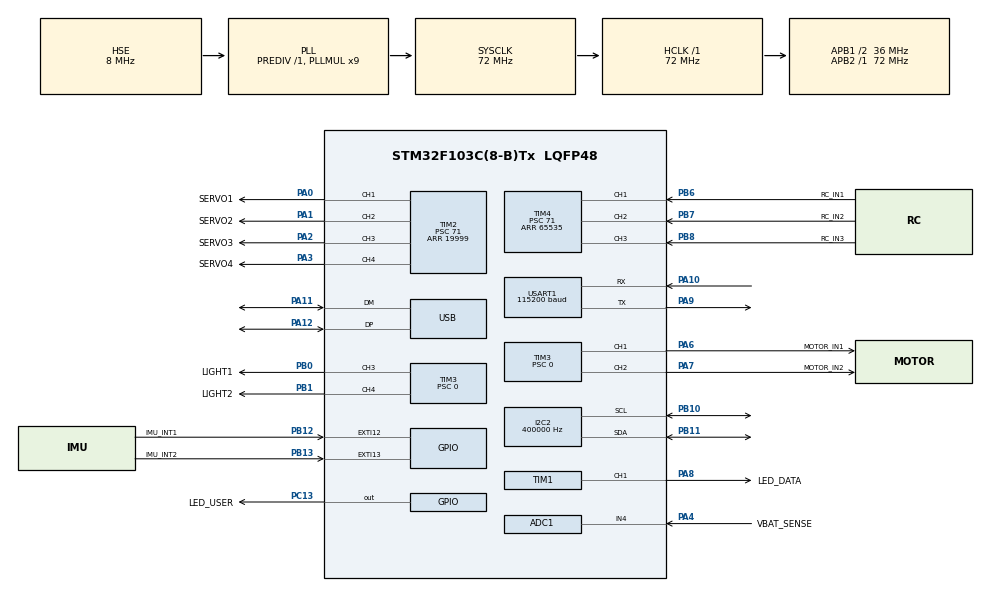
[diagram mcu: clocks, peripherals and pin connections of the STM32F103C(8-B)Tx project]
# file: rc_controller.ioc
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ADC1.Channel-0\#ChannelRegularConversion=ADC_CHANNEL_4
ADC1.NbrOfConversionFlag=1
ADC1.Rank-0\#ChannelRegularConversion=1
ADC1.SamplingTime-0\#ChannelRegularConversion=ADC_SAMPLETIME_1CYCLE_5
ADC1.master=1
Dma.Request0=TIM1_CH1
Dma.TIM1_CH1.0.Direction=DMA_MEMORY_TO_PERIPH
Dma.TIM1_CH1.0.Instance=DMA1_Channel2
Dma.TIM1_CH1.0.MemDataAlignment=DMA_MDATAALIGN_HALFWORD
Dma.TIM1_CH1.0.MemInc=DMA_MINC_ENABLE
Dma.TIM1_CH1.0.Mode=DMA_NORMAL
Dma.TIM1_CH1.0.PeriphDataAlignment=DMA_PDATAALIGN_HALFWORD
Dma.TIM1_CH1.0.PeriphInc=DMA_PINC_DISABLE
Dma.TIM1_CH1.0.Priority=DMA_PRIORITY_HIGH
I2C2.ClockSpeed=400000
Mcu.Family=STM32F1
Mcu.Name=STM32F103C(8-B)Tx
Mcu.Package=LQFP48
NVIC.DMA1_Channel2_IRQn=true\:0\:0\:false\:false\:true\:false\:true\:true
NVIC.EXTI15_10_IRQn=true\:0\:0\:false\:false\:true\:true\:true\:true
NVIC.PriorityGroup=NVIC_PRIORITYGROUP_4
NVIC.TIM4_IRQn=true\:0\:0\:false\:false\:true\:true\:true\:true
NVIC.USB_LP_CAN1_RX0_IRQn=true\:0\:0\:false\:false\:true\:false\:true\:true
PA0-WKUP.GPIO_Label=SERVO1
PA0-WKUP.Signal=S_TIM2_CH1_ETR
PA1.GPIO_Label=SERVO2
PA1.Signal=S_TIM2_CH2
PA10.Mode=Asynchronous
PA10.Signal=USART1_RX
PA11.Mode=Device
PA11.Signal=USB_DM
PA12.Mode=Device
PA12.Signal=USB_DP
PA13.Mode=Trace_Asynchronous_SW
PA13.Signal=SYS_JTMS-SWDIO
PA14.Mode=Trace_Asynchronous_SW
PA14.Signal=SYS_JTCK-SWCLK
PA2.GPIO_Label=SERVO3
PA2.Signal=S_TIM2_CH3
PA3.GPIO_Label=SERVO4
PA3.Signal=S_TIM2_CH4
PA4.GPIO_Label=VBAT_SENSE
PA4.Signal=ADCx_IN4
PA6.GPIO_Label=MOTOR_IN1
PA6.Signal=S_TIM3_CH1
PA7.GPIO_Label=MOTOR_IN2
PA7.Signal=S_TIM3_CH2
PA8.GPIO_Label=LED_DATA
PA8.Signal=S_TIM1_CH1
PA9.Mode=Asynchronous
PA9.Signal=USART1_TX
PB0.GPIO_Label=LIGHT1
PB0.Signal=S_TIM3_CH3
PB1.GPIO_Label=LIGHT2
PB1.Signal=S_TIM3_CH4
PB10.Mode=I2C
PB10.Signal=I2C2_SCL
PB11.Mode=I2C
PB11.Signal=I2C2_SDA
PB12.GPIO_Label=IMU_INT1
PB12.GPIO_ModeDefaultEXTI=GPIO_MODE_IT_RISING
PB12.Signal=GPXTI12
PB13.GPIO_Label=IMU_INT2
PB13.GPIO_ModeDefaultEXTI=GPIO_MODE_IT_RISING
PB13.Signal=GPXTI13
PB3.Mode=Trace_Asynchronous_SW
PB3.Signal=SYS_JTDO-TRACESWO
PB6.GPIO_Label=RC_IN1
PB6.Signal=S_TIM4_CH1
PB7.GPIO_Label=RC_IN2
PB7.Signal=S_TIM4_CH2
PB8.GPIO_Label=RC_IN3
PB8.Signal=S_TIM4_CH3
PC13-TAMPER-RTC.GPIO_Label=LED_USER
PC13-TAMPER-RTC.PinState=GPIO_PIN_SET
PC13-TAMPER-RTC.Signal=GPIO_Output
PD0-OSC_IN.Mode=HSE-External-Oscillator
PD0-OSC_IN.Signal=RCC_OSC_IN
PD1-OSC_OUT.Mode=HSE-External-Oscillator
PD1-OSC_OUT.Signal=RCC_OSC_OUT
ProjectManager.HeapSize=0x200
ProjectManager.StackSize=0x400
ProjectManager.TargetToolchain=CMake
RCC.ADCPresc=RCC_ADCPCLK2_DIV6
RCC.AHBFreq_Value=72000000
RCC.APB1CLKDivider=RCC_HCLK_DIV2
RCC.APB1Freq_Value=36000000
RCC.APB1TimFreq_Value=72000000
RCC.APB2Freq_Value=72000000
RCC.APB2TimFreq_Value=72000000
RCC.HCLKFreq_Value=72000000
RCC.PLLMUL=RCC_PLL_MUL9
RCC.PLLSourceVirtual=RCC_PLLSOURCE_HSE
RCC.SYSCLKFreq_VALUE=72000000
RCC.SYSCLKSource=RCC_SYSCLKSOURCE_PLLCLK
RCC.USBFreq_Value=48000000
RCC.USBPrescaler=RCC_USBCLKSOURCE_PLL_DIV1_5
SH.ADCx_IN4.0=ADC1_IN4,IN4
SH.S_TIM1_CH1.0=TIM1_CH1,PWM Generation1 CH1
SH.S_TIM2_CH1_ETR.0=TIM2_CH1,PWM Generation1 CH1
SH.S_TIM2_CH2.0=TIM2_CH2,PWM Generation2 CH2
SH.S_TIM2_CH3.0=TIM2_CH3,PWM Generation3 CH3
SH.S_TIM2_CH4.0=TIM2_CH4,PWM Generation4 CH4
SH.S_TIM3_CH1.0=TIM3_CH1,PWM Generation1 CH1
SH.S_TIM3_CH2.0=TIM3_CH2,PWM Generation2 CH2
SH.S_TIM3_CH3.0=TIM3_CH3,PWM Generation3 CH3
SH.S_TIM3_CH4.0=TIM3_CH4,PWM Generation4 CH4
SH.S_TIM4_CH1.0=TIM4_CH1,Input_Capture1_from_TI1
SH.S_TIM4_CH2.0=TIM4_CH2,Input_Capture2_from_TI2
SH.S_TIM4_CH3.0=TIM4_CH3,Input_Capture3_from_TI3
TIM1.Channel-PWM\ Generation1\ CH1=TIM_CHANNEL_1
TIM1.Period=89
TIM1.Prescaler=0
TIM2.Channel-PWM\ Generation1\ CH1=TIM_CHANNEL_1
TIM2.Channel-PWM\ Generation2\ CH2=TIM_CHANNEL_2
TIM2.Channel-PWM\ Generation3\ CH3=TIM_CHANNEL_3
TIM2.Channel-PWM\ Generation4\ CH4=TIM_CHANNEL_4
TIM2.Period=19999
TIM2.Prescaler=71
TIM2.Pulse-PWM\ Generation1\ CH1=1500
TIM2.Pulse-PWM\ Generation2\ CH2=1500
TIM2.Pulse-PWM\ Generation3\ CH3=1500
TIM2.Pulse-PWM\ Generation4\ CH4=1500
TIM3.Channel-PWM\ Generation1\ CH1=TIM_CHANNEL_1
TIM3.Channel-PWM\ Generation2\ CH2=TIM_CHANNEL_2
TIM3.Channel-PWM\ Generation3\ CH3=TIM_CHANNEL_3
TIM3.Channel-PWM\ Generation4\ CH4=TIM_CHANNEL_4
TIM3.Period=3599
TIM3.Prescaler=0
TIM4.Channel-Input_Capture1_from_TI1=TIM_CHANNEL_1
TIM4.Channel-Input_Capture2_from_TI2=TIM_CHANNEL_2
TIM4.Channel-Input_Capture3_from_TI3=TIM_CHANNEL_3
TIM4.Period=65535
TIM4.Prescaler=71
USART1.BaudRate=115200
USART1.VirtualMode=VM_ASYNC
USB_DEVICE.CLASS_NAME_FS=CDC
USB_DEVICE.VirtualMode=Cdc
USB_DEVICE.VirtualModeFS=Cdc_FS
VP_TIM1_VS_ClockSourceINT.Mode=Internal
VP_TIM2_VS_ClockSourceINT.Mode=Internal
VP_TIM3_VS_ClockSourceINT.Mode=Internal
VP_TIM4_VS_ClockSourceINT.Mode=Internal
VP_USB_DEVICE_VS_USB_DEVICE_CDC_FS.Mode=CDC_FS
board=custom

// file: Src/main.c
/* USER CODE BEGIN Header */
/**
  ******************************************************************************
  * @file           : main.c
  * @brief          : Main program body
  ******************************************************************************
  * @attention
  *
  * Copyright (c) 2026 STMicroelectronics.
  * All rights reserved.
  *
  * This software is licensed under terms that can be found in the LICENSE file
  * in the root directory of this software component.
  * If no LICENSE file comes with this software, it is provided AS-IS.
  *
  ******************************************************************************
  */
/* USER CODE END Header */
#include "main.h"
#include "usb_device.h"

/* USER CODE BEGIN Includes */
#include "app.h"
/* USER CODE END Includes */

ADC_HandleTypeDef hadc1;

I2C_HandleTypeDef hi2c2;

TIM_HandleTypeDef htim1;
TIM_HandleTypeDef htim2;
TIM_HandleTypeDef htim3;
TIM_HandleTypeDef htim4;
DMA_HandleTypeDef hdma_tim1_ch1;

UART_HandleTypeDef huart1;

void SystemClock_Config(void);
static void MX_GPIO_Init(void);
static void MX_DMA_Init(void);
static void MX_ADC1_Init(void);
static void MX_I2C2_Init(void);
static void MX_TIM1_Init(void);
static void MX_TIM2_Init(void);
static void MX_TIM3_Init(void);
static void MX_TIM4_Init(void);
static void MX_USART1_UART_Init(void);

int main(void)
{

  /* MCU Configuration--------------------------------------------------------*/

  /* Reset of all peripherals, Initializes the Flash interface and the Systick. */
  HAL_Init();

  /* Configure the system clock */
  SystemClock_Config();

  /* Initialize all configured peripherals */
  MX_GPIO_Init();
  MX_DMA_Init();
  MX_ADC1_Init();
  MX_I2C2_Init();
  MX_TIM1_Init();
  MX_TIM2_Init();
  MX_TIM3_Init();
  MX_TIM4_Init();
  MX_USART1_UART_Init();
  MX_USB_DEVICE_Init();
  /* USER CODE BEGIN 2 */
  app_init();
  /* USER CODE END 2 */

  /* Infinite loop */
  while (1)
  {

    /* USER CODE BEGIN 3 */
    app_loop();
  }
  /* USER CODE END 3 */
}

void SystemClock_Config(void)
{
  RCC_OscInitTypeDef RCC_OscInitStruct = {0};
  RCC_ClkInitTypeDef RCC_ClkInitStruct = {0};
  RCC_PeriphCLKInitTypeDef PeriphClkInit = {0};

  /** Initializes the RCC Oscillators according to the specified parameters
  * in the RCC_OscInitTypeDef structure.
  */
  RCC_OscInitStruct.OscillatorType = RCC_OSCILLATORTYPE_HSE;
  RCC_OscInitStruct.HSEState = RCC_HSE_ON;
  RCC_OscInitStruct.HSEPredivValue = RCC_HSE_PREDIV_DIV1;
  RCC_OscInitStruct.HSIState = RCC_HSI_ON;
  RCC_OscInitStruct.PLL.PLLState = RCC_PLL_ON;
  RCC_OscInitStruct.PLL.PLLSource = RCC_PLLSOURCE_HSE;
  RCC_OscInitStruct.PLL.PLLMUL = RCC_PLL_MUL9;
  if (HAL_RCC_OscConfig(&RCC_OscInitStruct) != HAL_OK)
  {
    Error_Handler();
  }

  /** Initializes the CPU, AHB and APB buses clocks
  */
  RCC_ClkInitStruct.ClockType = RCC_CLOCKTYPE_HCLK|RCC_CLOCKTYPE_SYSCLK
                              |RCC_CLOCKTYPE_PCLK1|RCC_CLOCKTYPE_PCLK2;
  RCC_ClkInitStruct.SYSCLKSource = RCC_SYSCLKSOURCE_PLLCLK;
  RCC_ClkInitStruct.AHBCLKDivider = RCC_SYSCLK_DIV1;
  RCC_ClkInitStruct.APB1CLKDivider = RCC_HCLK_DIV2;
  RCC_ClkInitStruct.APB2CLKDivider = RCC_HCLK_DIV1;

  if (HAL_RCC_ClockConfig(&RCC_ClkInitStruct, FLASH_LATENCY_2) != HAL_OK)
  {
    Error_Handler();
  }
  PeriphClkInit.PeriphClockSelection = RCC_PERIPHCLK_ADC|RCC_PERIPHCLK_USB;
  PeriphClkInit.AdcClockSelection = RCC_ADCPCLK2_DIV6;
  PeriphClkInit.UsbClockSelection = RCC_USBCLKSOURCE_PLL_DIV1_5;
  if (HAL_RCCEx_PeriphCLKConfig(&PeriphClkInit) != HAL_OK)
  {
    Error_Handler();
  }
}

static void MX_ADC1_Init(void)
{

  ADC_ChannelConfTypeDef sConfig = {0};

  /** Common config
  */
  hadc1.Instance = ADC1;
  hadc1.Init.ScanConvMode = ADC_SCAN_DISABLE;
  hadc1.Init.ContinuousConvMode = DISABLE;
  hadc1.Init.DiscontinuousConvMode = DISABLE;
  hadc1.Init.ExternalTrigConv = ADC_SOFTWARE_START;
  hadc1.Init.DataAlign = ADC_DATAALIGN_RIGHT;
  hadc1.Init.NbrOfConversion = 1;
  if (HAL_ADC_Init(&hadc1) != HAL_OK)
  {
    Error_Handler();
  }

  /** Configure Regular Channel
  */
  sConfig.Channel = ADC_CHANNEL_4;
  sConfig.Rank = ADC_REGULAR_RANK_1;
  sConfig.SamplingTime = ADC_SAMPLETIME_1CYCLE_5;
  if (HAL_ADC_ConfigChannel(&hadc1, &sConfig) != HAL_OK)
  {
    Error_Handler();
  }

}

static void MX_I2C2_Init(void)
{

  hi2c2.Instance = I2C2;
  hi2c2.Init.ClockSpeed = 400000;
  hi2c2.Init.DutyCycle = I2C_DUTYCYCLE_2;
  hi2c2.Init.OwnAddress1 = 0;
  hi2c2.Init.AddressingMode = I2C_ADDRESSINGMODE_7BIT;
  hi2c2.Init.DualAddressMode = I2C_DUALADDRESS_DISABLE;
  hi2c2.Init.OwnAddress2 = 0;
  hi2c2.Init.GeneralCallMode = I2C_GENERALCALL_DISABLE;
  hi2c2.Init.NoStretchMode = I2C_NOSTRETCH_DISABLE;
  if (HAL_I2C_Init(&hi2c2) != HAL_OK)
  {
    Error_Handler();
  }

}

static void MX_TIM1_Init(void)
{

  TIM_ClockConfigTypeDef sClockSourceConfig = {0};
  TIM_MasterConfigTypeDef sMasterConfig = {0};
  TIM_OC_InitTypeDef sConfigOC = {0};
  TIM_BreakDeadTimeConfigTypeDef sBreakDeadTimeConfig = {0};

  htim1.Instance = TIM1;
  htim1.Init.Prescaler = 0;
  htim1.Init.CounterMode = TIM_COUNTERMODE_UP;
  htim1.Init.Period = 89;
  htim1.Init.ClockDivision = TIM_CLOCKDIVISION_DIV1;
  htim1.Init.RepetitionCounter = 0;
  htim1.Init.AutoReloadPreload = TIM_AUTORELOAD_PRELOAD_DISABLE;
  if (HAL_TIM_Base_Init(&htim1) != HAL_OK)
  {
    Error_Handler();
  }
  sClockSourceConfig.ClockSource = TIM_CLOCKSOURCE_INTERNAL;
  if (HAL_TIM_ConfigClockSource(&htim1, &sClockSourceConfig) != HAL_OK)
  {
    Error_Handler();
  }
  if (HAL_TIM_PWM_Init(&htim1) != HAL_OK)
  {
    Error_Handler();
  }
  sMasterConfig.MasterOutputTrigger = TIM_TRGO_RESET;
  sMasterConfig.MasterSlaveMode = TIM_MASTERSLAVEMODE_DISABLE;
  if (HAL_TIMEx_MasterConfigSynchronization(&htim1, &sMasterConfig) != HAL_OK)
  {
    Error_Handler();
  }
  sConfigOC.OCMode = TIM_OCMODE_PWM1;
  sConfigOC.Pulse = 0;
  sConfigOC.OCPolarity = TIM_OCPOLARITY_HIGH;
  sConfigOC.OCNPolarity = TIM_OCNPOLARITY_HIGH;
  sConfigOC.OCFastMode = TIM_OCFAST_DISABLE;
  sConfigOC.OCIdleState = TIM_OCIDLESTATE_RESET;
  sConfigOC.OCNIdleState = TIM_OCNIDLESTATE_RESET;
  if (HAL_TIM_PWM_ConfigChannel(&htim1, &sConfigOC, TIM_CHANNEL_1) != HAL_OK)
  {
    Error_Handler();
  }
  sBreakDeadTimeConfig.OffStateRunMode = TIM_OSSR_DISABLE;
  sBreakDeadTimeConfig.OffStateIDLEMode = TIM_OSSI_DISABLE;
  sBreakDeadTimeConfig.LockLevel = TIM_LOCKLEVEL_OFF;
  sBreakDeadTimeConfig.DeadTime = 0;
  sBreakDeadTimeConfig.BreakState = TIM_BREAK_DISABLE;
  sBreakDeadTimeConfig.BreakPolarity = TIM_BREAKPOLARITY_HIGH;
  sBreakDeadTimeConfig.AutomaticOutput = TIM_AUTOMATICOUTPUT_DISABLE;
  if (HAL_TIMEx_ConfigBreakDeadTime(&htim1, &sBreakDeadTimeConfig) != HAL_OK)
  {
    Error_Handler();
  }
  HAL_TIM_MspPostInit(&htim1);

}

static void MX_TIM2_Init(void)
{

  TIM_ClockConfigTypeDef sClockSourceConfig = {0};
  TIM_MasterConfigTypeDef sMasterConfig = {0};
  TIM_OC_InitTypeDef sConfigOC = {0};

  htim2.Instance = TIM2;
  htim2.Init.Prescaler = 71;
  htim2.Init.CounterMode = TIM_COUNTERMODE_UP;
  htim2.Init.Period = 19999;
  htim2.Init.ClockDivision = TIM_CLOCKDIVISION_DIV1;
  htim2.Init.AutoReloadPreload = TIM_AUTORELOAD_PRELOAD_DISABLE;
  if (HAL_TIM_Base_Init(&htim2) != HAL_OK)
  {
    Error_Handler();
  }
  sClockSourceConfig.ClockSource = TIM_CLOCKSOURCE_INTERNAL;
  if (HAL_TIM_ConfigClockSource(&htim2, &sClockSourceConfig) != HAL_OK)
  {
    Error_Handler();
  }
  if (HAL_TIM_PWM_Init(&htim2) != HAL_OK)
  {
    Error_Handler();
  }
  sMasterConfig.MasterOutputTrigger = TIM_TRGO_RESET;
  sMasterConfig.MasterSlaveMode = TIM_MASTERSLAVEMODE_DISABLE;
  if (HAL_TIMEx_MasterConfigSynchronization(&htim2, &sMasterConfig) != HAL_OK)
  {
    Error_Handler();
  }
  sConfigOC.OCMode = TIM_OCMODE_PWM1;
  sConfigOC.Pulse = 1500;
  sConfigOC.OCPolarity = TIM_OCPOLARITY_HIGH;
  sConfigOC.OCFastMode = TIM_OCFAST_DISABLE;
  if (HAL_TIM_PWM_ConfigChannel(&htim2, &sConfigOC, TIM_CHANNEL_1) != HAL_OK)
  {
    Error_Handler();
  }
  if (HAL_TIM_PWM_ConfigChannel(&htim2, &sConfigOC, TIM_CHANNEL_2) != HAL_OK)
  {
    Error_Handler();
  }
  if (HAL_TIM_PWM_ConfigChannel(&htim2, &sConfigOC, TIM_CHANNEL_3) != HAL_OK)
  {
    Error_Handler();
  }
  if (HAL_TIM_PWM_ConfigChannel(&htim2, &sConfigOC, TIM_CHANNEL_4) != HAL_OK)
  {
    Error_Handler();
  }
  HAL_TIM_MspPostInit(&htim2);

}

static void MX_TIM3_Init(void)
{

  TIM_ClockConfigTypeDef sClockSourceConfig = {0};
  TIM_MasterConfigTypeDef sMasterConfig = {0};
  TIM_OC_InitTypeDef sConfigOC = {0};

  htim3.Instance = TIM3;
  htim3.Init.Prescaler = 0;
  htim3.Init.CounterMode = TIM_COUNTERMODE_UP;
  htim3.Init.Period = 3599;
  htim3.Init.ClockDivision = TIM_CLOCKDIVISION_DIV1;
  htim3.Init.AutoReloadPreload = TIM_AUTORELOAD_PRELOAD_DISABLE;
  if (HAL_TIM_Base_Init(&htim3) != HAL_OK)
  {
    Error_Handler();
  }
  sClockSourceConfig.ClockSource = TIM_CLOCKSOURCE_INTERNAL;
  if (HAL_TIM_ConfigClockSource(&htim3, &sClockSourceConfig) != HAL_OK)
  {
    Error_Handler();
  }
  if (HAL_TIM_PWM_Init(&htim3) != HAL_OK)
  {
    Error_Handler();
  }
  sMasterConfig.MasterOutputTrigger = TIM_TRGO_RESET;
  sMasterConfig.MasterSlaveMode = TIM_MASTERSLAVEMODE_DISABLE;
  if (HAL_TIMEx_MasterConfigSynchronization(&htim3, &sMasterConfig) != HAL_OK)
  {
    Error_Handler();
  }
  sConfigOC.OCMode = TIM_OCMODE_PWM1;
  sConfigOC.Pulse = 0;
  sConfigOC.OCPolarity = TIM_OCPOLARITY_HIGH;
  sConfigOC.OCFastMode = TIM_OCFAST_DISABLE;
  if (HAL_TIM_PWM_ConfigChannel(&htim3, &sConfigOC, TIM_CHANNEL_1) != HAL_OK)
  {
    Error_Handler();
  }
  if (HAL_TIM_PWM_ConfigChannel(&htim3, &sConfigOC, TIM_CHANNEL_2) != HAL_OK)
  {
    Error_Handler();
  }
  if (HAL_TIM_PWM_ConfigChannel(&htim3, &sConfigOC, TIM_CHANNEL_3) != HAL_OK)
  {
    Error_Handler();
  }
  if (HAL_TIM_PWM_ConfigChannel(&htim3, &sConfigOC, TIM_CHANNEL_4) != HAL_OK)
  {
    Error_Handler();
  }
  HAL_TIM_MspPostInit(&htim3);

}

static void MX_TIM4_Init(void)
{

  TIM_ClockConfigTypeDef sClockSourceConfig = {0};
  TIM_MasterConfigTypeDef sMasterConfig = {0};
  TIM_IC_InitTypeDef sConfigIC = {0};

  htim4.Instance = TIM4;
  htim4.Init.Prescaler = 71;
  htim4.Init.CounterMode = TIM_COUNTERMODE_UP;
  htim4.Init.Period = 65535;
  htim4.Init.ClockDivision = TIM_CLOCKDIVISION_DIV1;
  htim4.Init.AutoReloadPreload = TIM_AUTORELOAD_PRELOAD_DISABLE;
  if (HAL_TIM_Base_Init(&htim4) != HAL_OK)
  {
    Error_Handler();
  }
  sClockSourceConfig.ClockSource = TIM_CLOCKSOURCE_INTERNAL;
  if (HAL_TIM_ConfigClockSource(&htim4, &sClockSourceConfig) != HAL_OK)
  {
    Error_Handler();
  }
  if (HAL_TIM_IC_Init(&htim4) != HAL_OK)
  {
    Error_Handler();
  }
  sMasterConfig.MasterOutputTrigger = TIM_TRGO_RESET;
  sMasterConfig.MasterSlaveMode = TIM_MASTERSLAVEMODE_DISABLE;
  if (HAL_TIMEx_MasterConfigSynchronization(&htim4, &sMasterConfig) != HAL_OK)
  {
    Error_Handler();
  }
  sConfigIC.ICPolarity = TIM_INPUTCHANNELPOLARITY_RISING;
  sConfigIC.ICSelection = TIM_ICSELECTION_DIRECTTI;
  sConfigIC.ICPrescaler = TIM_ICPSC_DIV1;
  sConfigIC.ICFilter = 0;
  if (HAL_TIM_IC_ConfigChannel(&htim4, &sConfigIC, TIM_CHANNEL_1) != HAL_OK)
  {
    Error_Handler();
  }
  if (HAL_TIM_IC_ConfigChannel(&htim4, &sConfigIC, TIM_CHANNEL_2) != HAL_OK)
  {
    Error_Handler();
  }
  if (HAL_TIM_IC_ConfigChannel(&htim4, &sConfigIC, TIM_CHANNEL_3) != HAL_OK)
  {
    Error_Handler();
  }

}

static void MX_USART1_UART_Init(void)
{

  huart1.Instance = USART1;
  huart1.Init.BaudRate = 115200;
  huart1.Init.WordLength = UART_WORDLENGTH_8B;
  huart1.Init.StopBits = UART_STOPBITS_1;
  huart1.Init.Parity = UART_PARITY_NONE;
  huart1.Init.Mode = UART_MODE_TX_RX;
  huart1.Init.HwFlowCtl = UART_HWCONTROL_NONE;
  huart1.Init.OverSampling = UART_OVERSAMPLING_16;
  if (HAL_UART_Init(&huart1) != HAL_OK)
  {
    Error_Handler();
  }

}

static void MX_DMA_Init(void)
{

  /* DMA controller clock enable */
  __HAL_RCC_DMA1_CLK_ENABLE();

  /* DMA interrupt init */
  /* DMA1_Channel2_IRQn interrupt configuration */
  HAL_NVIC_SetPriority(DMA1_Channel2_IRQn, 0, 0);
  HAL_NVIC_EnableIRQ(DMA1_Channel2_IRQn);

}

static void MX_GPIO_Init(void)
{
  GPIO_InitTypeDef GPIO_InitStruct = {0};

  /* GPIO Ports Clock Enable */
  __HAL_RCC_GPIOC_CLK_ENABLE();
  __HAL_RCC_GPIOD_CLK_ENABLE();
  __HAL_RCC_GPIOA_CLK_ENABLE();
  __HAL_RCC_GPIOB_CLK_ENABLE();

  /*Configure GPIO pin Output Level */
  HAL_GPIO_WritePin(LED_USER_GPIO_Port, LED_USER_Pin, GPIO_PIN_SET);

  /*Configure GPIO pin : LED_USER_Pin */
  GPIO_InitStruct.Pin = LED_USER_Pin;
  GPIO_InitStruct.Mode = GPIO_MODE_OUTPUT_PP;
  GPIO_InitStruct.Pull = GPIO_NOPULL;
  GPIO_InitStruct.Speed = GPIO_SPEED_FREQ_LOW;
  HAL_GPIO_Init(LED_USER_GPIO_Port, &GPIO_InitStruct);

  /*Configure GPIO pins : IMU_INT1_Pin IMU_INT2_Pin */
  GPIO_InitStruct.Pin = IMU_INT1_Pin|IMU_INT2_Pin;
  GPIO_InitStruct.Mode = GPIO_MODE_IT_RISING;
  GPIO_InitStruct.Pull = GPIO_NOPULL;
  HAL_GPIO_Init(GPIOB, &GPIO_InitStruct);

  /* EXTI interrupt init*/
  HAL_NVIC_SetPriority(EXTI15_10_IRQn, 0, 0);
  HAL_NVIC_EnableIRQ(EXTI15_10_IRQn);

}

void Error_Handler(void)
{
  __disable_irq();
  while (1)
  {
  }
}
